VERSION ""

NS_ :

BS_:

BU_:

BO_ 3221225472 VECTOR__INDEPENDENT_SIG_MSG: 0 Vector__XXX
 SG_ gear : 0|16@0+ (1,0) [0|0] "" Vector__XXX

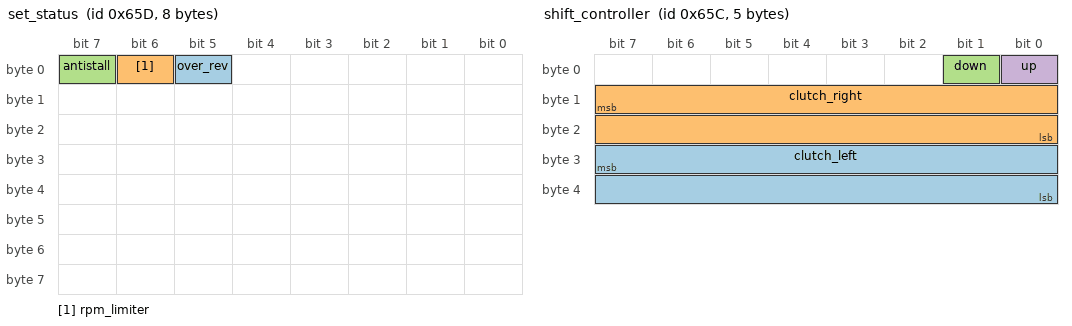
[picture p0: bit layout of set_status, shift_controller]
BO_ 1629 set_status: 8 Vector__XXX
 SG_ over_rev : 5|1@0+ (1,0) [0|0] "" Vector__XXX
 SG_ rpm_limiter : 6|1@0+ (1,0) [0|0] "" Vector__XXX
 SG_ antistall : 7|1@0+ (1,0) [0|0] "" Vector__XXX

BO_ 1628 shift_controller: 5 Vector__XXX
 SG_ clutch_left : 31|16@0- (0.01,0) [0|0] "" Vector__XXX
 SG_ clutch_right : 15|16@0- (0.01,0) [0|0] "" Vector__XXX
 SG_ down : 1|1@0- (1,0) [0|1] "" Vector__XXX
 SG_ up : 0|1@0- (1,0) [0|1] "" Vector__XXX

BO_ 1625 clutch: 4 Vector__XXX
 SG_ position_percentage : 23|16@0+ (1,0) [0|0] "" Vector__XXX
 SG_ position : 7|16@0+ (1,0) [0|0] "" Vector__XXX

BO_ 1626 set_clutch: 4 Vector__XXX
 SG_ set_state : 23|16@0+ (1,0) [0|0] "" Vector__XXX
 SG_ set_position : 7|16@0+ (1,0) [0|0] "" Vector__XXX

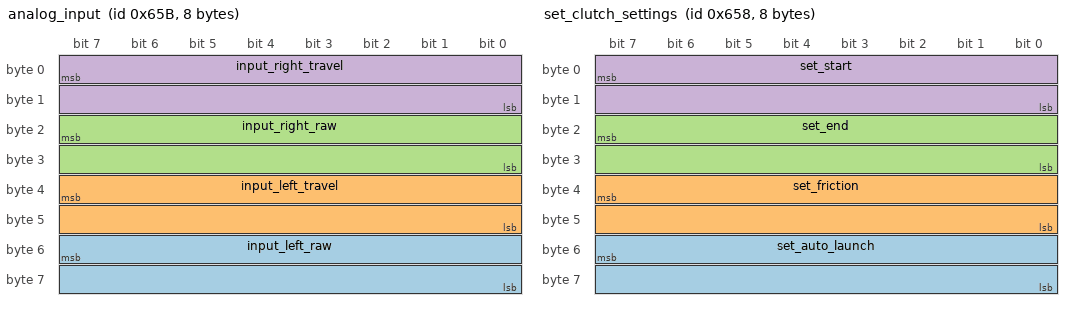
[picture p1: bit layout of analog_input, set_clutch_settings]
BO_ 1627 analog_input: 8 Vector__XXX
 SG_ input_left_raw : 55|16@0+ (1,0) [0|0] "" Vector__XXX
 SG_ input_left_travel : 39|16@0+ (1,0) [0|0] "%" Vector__XXX
 SG_ input_right_raw : 23|16@0+ (1,0) [0|0] "" Vector__XXX
 SG_ input_right_travel : 7|16@0+ (1,0) [0|0] "%" Vector__XXX

BO_ 1624 set_clutch_settings: 8 Vector__XXX
 SG_ set_auto_launch : 55|16@0+ (1,0) [0|0] "" Vector__XXX
 SG_ set_friction : 39|16@0+ (1,0) [0|0] "" Vector__XXX
 SG_ set_end : 23|16@0+ (1,0) [0|0] "" Vector__XXX
 SG_ set_start : 7|16@0+ (1,0) [0|0] "" Vector__XXX

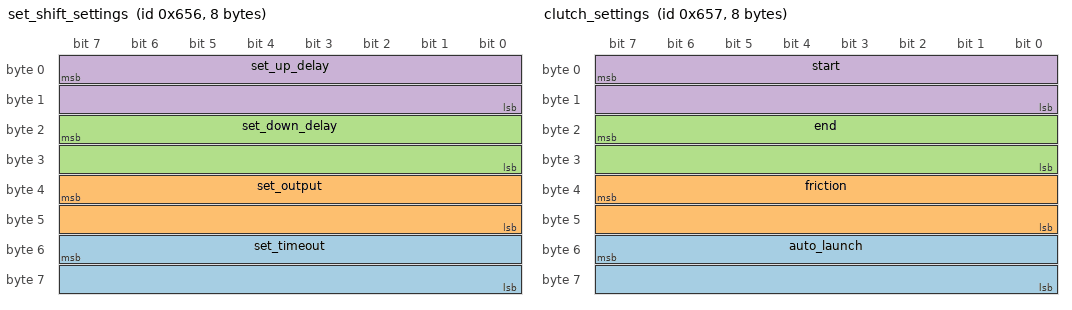
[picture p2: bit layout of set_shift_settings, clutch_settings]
BO_ 1622 set_shift_settings: 8 Vector__XXX
 SG_ set_timeout : 55|16@0+ (1,0) [0|0] "ms" Vector__XXX
 SG_ set_output : 39|16@0+ (1,0) [0|0] "ms" Vector__XXX
 SG_ set_down_delay : 23|16@0+ (1,0) [0|0] "ms" Vector__XXX
 SG_ set_up_delay : 7|16@0+ (1,0) [0|0] "ms" Vector__XXX

BO_ 1623 clutch_settings: 8 Vector__XXX
 SG_ auto_launch : 55|16@0+ (1,0) [0|0] "" Vector__XXX
 SG_ friction : 39|16@0+ (1,0) [0|0] "" Vector__XXX
 SG_ end : 23|16@0+ (1,0) [0|0] "" Vector__XXX
 SG_ start : 7|16@0+ (1,0) [0|0] "" Vector__XXX

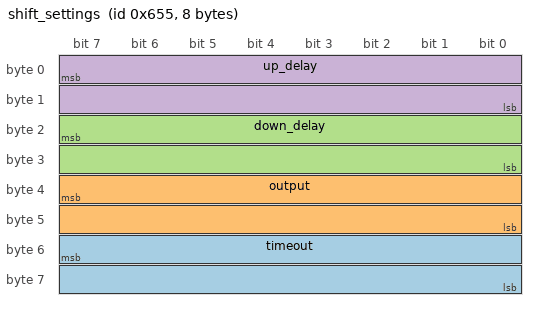
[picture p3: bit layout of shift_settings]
BO_ 1621 shift_settings: 8 Vector__XXX
 SG_ timeout : 55|16@0+ (1,0) [0|0] "ms" Vector__XXX
 SG_ output : 39|16@0+ (1,0) [0|0] "ms" Vector__XXX
 SG_ down_delay : 23|16@0+ (1,0) [0|0] "ms" Vector__XXX
 SG_ up_delay : 7|16@0+ (1,0) [0|0] "ms" Vector__XXX

CM_ BO_ 3221225472 "This is a message for not used signals, created by Vector CANdb++ DBC OLE DB Provider.";
BA_DEF_  "BusType" STRING ;
BA_DEF_DEF_  "BusType" "CAN";
